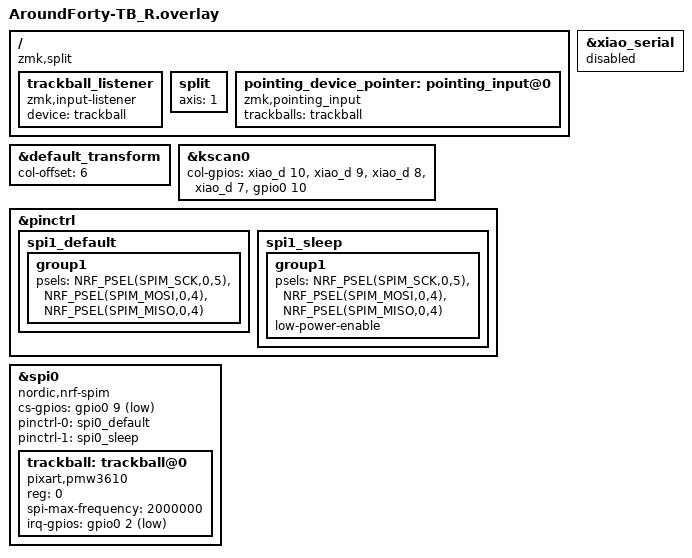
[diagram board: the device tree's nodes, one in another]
#include "AroundForty-TB.dtsi"


&default_transform {
    col-offset = <6>;
};

&kscan0 {
        col-gpios
            = <&xiao_d 10 GPIO_ACTIVE_HIGH>
            , <&xiao_d 9 GPIO_ACTIVE_HIGH> 
            , <&xiao_d 8 GPIO_ACTIVE_HIGH> 
            , <&xiao_d 7 GPIO_ACTIVE_HIGH> 
            , <&gpio0 10 GPIO_ACTIVE_HIGH>
            ;
};

/ {
    trackball_listener {
        compatible = "zmk,input-listener";
        device = <&trackball>;

    };
};

&pinctrl {
    spi1_default: spi1_default { group1 {
        psels = <NRF_PSEL(SPIM_SCK,0,5)>,
               <NRF_PSEL(SPIM_MOSI,0,4)>,
               <NRF_PSEL(SPIM_MISO,0,4)>;
    };};

    spi1_sleep: spi1_sleep { group1 {
        psels = <NRF_PSEL(SPIM_SCK,0,5)>,
               <NRF_PSEL(SPIM_MOSI,0,4)>,
               <NRF_PSEL(SPIM_MISO,0,4)>;
        low-power-enable;
    };};
};

&xiao_serial { status = "disabled"; };

&spi0 {
    status       = "okay";
    compatible   = "nordic,nrf-spim";

    cs-gpios      = <&gpio0 9 GPIO_ACTIVE_LOW>;          /* NCS  → P0.09 */
    pinctrl-0     = <&spi0_default>;
    pinctrl-1     = <&spi0_sleep>;
    pinctrl-names = "default", "sleep";

    trackball: trackball@0 {
        status            = "okay";
        compatible        = "pixart,pmw3610";
        reg               = <0>;
        spi-max-frequency = <2000000>;
        irq-gpios         = <&gpio0 2 (GPIO_ACTIVE_LOW | GPIO_PULL_UP)>; /* MOTION → P0.02 */
    };
};

/* — ここから追加 — */
/ {
    /* 1) Split ホストモードを有効化 */
    compatible = "zmk,split";
    split {
        status = "okay";
        axis   = <1>;
    };

    /* 2) 右手トラックボールをポインタ入力として定義 */
    pointing_device_pointer: pointing_input@0 {
        compatible = "zmk,pointing_input";
        trackballs = <&trackball>;
        status     = "okay";
    };
};
/* — 追加ここまで — */
